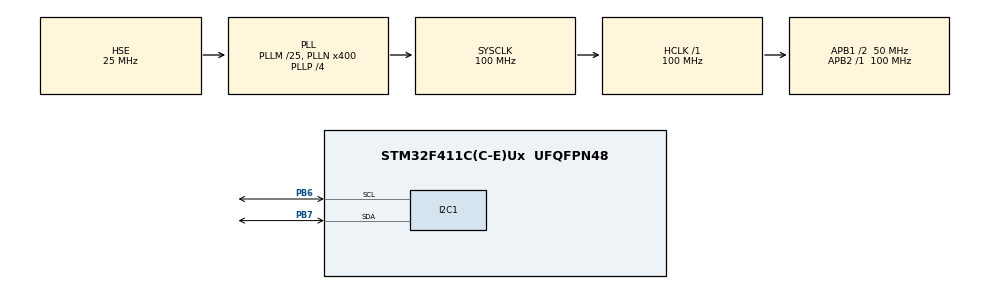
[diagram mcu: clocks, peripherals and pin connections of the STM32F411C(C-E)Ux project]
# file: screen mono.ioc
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I2C1.I2C_Mode=I2C_Fast
Mcu.Family=STM32F4
Mcu.Name=STM32F411C(C-E)Ux
Mcu.Package=UFQFPN48
NVIC.PriorityGroup=NVIC_PRIORITYGROUP_4
PB6.Mode=I2C
PB6.Signal=I2C1_SCL
PB7.Mode=I2C
PB7.Signal=I2C1_SDA
PH0\ -\ OSC_IN.Mode=HSE-External-Oscillator
PH0\ -\ OSC_IN.Signal=RCC_OSC_IN
PH1\ -\ OSC_OUT.Mode=HSE-External-Oscillator
PH1\ -\ OSC_OUT.Signal=RCC_OSC_OUT
ProjectManager.HeapSize=0x200
ProjectManager.StackSize=0x400
ProjectManager.TargetToolchain=STM32CubeIDE
RCC.48MHZClocksFreq_Value=100000000
RCC.AHBFreq_Value=100000000
RCC.APB1CLKDivider=RCC_HCLK_DIV2
RCC.APB1Freq_Value=50000000
RCC.APB1TimFreq_Value=100000000
RCC.APB2Freq_Value=100000000
RCC.APB2TimFreq_Value=100000000
RCC.CortexFreq_Value=100000000
RCC.HCLKFreq_Value=100000000
RCC.HSE_VALUE=25000000
RCC.HSI_VALUE=16000000
RCC.LSE_VALUE=32768
RCC.PLLM=25
RCC.PLLN=400
RCC.PLLP=RCC_PLLP_DIV4
RCC.PLLSourceVirtual=RCC_PLLSOURCE_HSE
RCC.SYSCLKFreq_VALUE=100000000
RCC.SYSCLKSource=RCC_SYSCLKSOURCE_PLLCLK
RCC.VCOOutputFreq_Value=400000000
board=custom

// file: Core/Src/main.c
/* USER CODE BEGIN Header */
/**
  ******************************************************************************
  * @file           : main.c
  * @brief          : Main program body
  ******************************************************************************
  * @attention
  *
  * Copyright (c) 2026 STMicroelectronics.
  * All rights reserved.
  *
  * This software is licensed under terms that can be found in the LICENSE file
  * in the root directory of this software component.
  * If no LICENSE file comes with this software, it is provided AS-IS.
  *
  ******************************************************************************
  */
/* USER CODE END Header */
#include "main.h"

/* USER CODE BEGIN PD */

#define SSD1315_I2C_ADDR  (0x3C << 1)

#define SCREEN_WIDTH 128
#define SCREEN_HEIGHT 64

/* USER CODE END PD */

I2C_HandleTypeDef hi2c1;

/* USER CODE BEGIN PV */

// Битовая матрица стандартного шрифта 8x16 (ASCII символы от ' ' до '~')
// Каждый байт — это одна строка символа шириной 8 пикселей. 1 - белый, 0 - черный.
const uint8_t font8x16[][16] = {
    // Здесь обычно находится весь массив ASCII. Ниже приведены только нужные нам символы для экономии места:
    ['H'] = {0x82, 0x82, 0x82, 0x82, 0x82, 0xFE, 0x82, 0x82, 0x82, 0x82, 0x82, 0x82, 0x82, 0x00, 0x00, 0x00},
    ['e'] = {0x00, 0x00, 0x00, 0x00, 0x00, 0x7C, 0x82, 0xFE, 0x80, 0x80, 0x82, 0x7C, 0x00, 0x00, 0x00, 0x00},
    ['l'] = {0x30, 0x10, 0x10, 0x10, 0x10, 0x10, 0x10, 0x10, 0x10, 0x10, 0x10, 0x18, 0x00, 0x00, 0x00, 0x00},
    ['o'] = {0x00, 0x00, 0x00, 0x00, 0x00, 0x7C, 0x82, 0x82, 0x82, 0x82, 0x82, 0x7C, 0x00, 0x00, 0x00, 0x00},
    [','] = {0x00, 0x00, 0x00, 0x00, 0x00, 0x00, 0x00, 0x00, 0x00, 0x00, 0x30, 0x30, 0x10, 0x20, 0x00, 0x00},
    [' '] = {0x00, 0x00, 0x00, 0x00, 0x00, 0x00, 0x00, 0x00, 0x00, 0x00, 0x00, 0x00, 0x00, 0x00, 0x00, 0x00},
    ['w'] = {0x00, 0x00, 0x00, 0x00, 0x00, 0x82, 0x82, 0x82, 0x92, 0x92, 0x92, 0x6C, 0x00, 0x00, 0x00, 0x00},
    ['r'] = {0x00, 0x00, 0x00, 0x00, 0x00, 0x9E, 0x62, 0x40, 0x40, 0x40, 0x40, 0xE0, 0x00, 0x00, 0x00, 0x00},
    ['d'] = {0x02, 0x02, 0x02, 0x7E, 0x82, 0x82, 0x82, 0x82, 0x82, 0x82, 0x86, 0x7A, 0x00, 0x00, 0x00, 0x00},
    ['!'] = {0x10, 0x10, 0x10, 0x10, 0x10, 0x10, 0x10, 0x10, 0x00, 0x00, 0x10, 0x10, 0x00, 0x00, 0x00, 0x00}
};

uint8_t screen_buffer[1024];

/* USER CODE END PV */

void SystemClock_Config(void);
static void MX_GPIO_Init(void);
static void MX_I2C1_Init(void);

/* USER CODE BEGIN 0 */

// Отправка одной управляющей команды
void SSD1315_WriteCommand(uint8_t cmd) {
    HAL_I2C_Mem_Write(&hi2c1, SSD1315_I2C_ADDR, 0x00, I2C_MEMADD_SIZE_8BIT, &cmd, 1, HAL_MAX_DELAY);
}

// Отправка всего буфера кадра на дисплей
void SSD1315_UpdateScreen(void) {
    // Возвращаем указатель адреса дисплея в начало (столбец 0, страница 0)
    SSD1315_WriteCommand(0x21); // Установка диапазона колонок
    SSD1315_WriteCommand(0);    // Старт
    SSD1315_WriteCommand(127);  // Конец

    SSD1315_WriteCommand(0x22); // Установка диапазона страниц (строк)
    SSD1315_WriteCommand(0);    // Старт
    SSD1315_WriteCommand(7);    // Конец (7 * 8 = 56, то есть до 63 строки)

    // Отправляем массив данных. Префикс 0x40 указывает, что это поток байт видеопамяти
    HAL_I2C_Mem_Write(&hi2c1, SSD1315_I2C_ADDR, 0x40, I2C_MEMADD_SIZE_8BIT, screen_buffer, 1024, HAL_MAX_DELAY);
}

void SSD1315_Init(void) {
    HAL_Delay(100); // Ждем стабилизации питания дисплея

    SSD1315_WriteCommand(0xAE); // Выключить дисплей (Sleep mode)

    SSD1315_WriteCommand(0x20); // Настройка адресации памяти
    SSD1315_WriteCommand(0x00); // 0x00 — Горизонтальная адресация (автоинкремент)

    SSD1315_WriteCommand(0xB0); // Установка стартового адреса страницы (0)

    SSD1315_WriteCommand(0xC8); // Переворот выходов COM (сканирование снизу вверх)
    SSD1315_WriteCommand(0x00); // Установка низшего адреса колонки
    SSD1315_WriteCommand(0x10); // Установка высшего адреса колонки
    SSD1315_WriteCommand(0x40); // Установка стартовой строки (0)

    SSD1315_WriteCommand(0x81); // Контрастность
    SSD1315_WriteCommand(0xCF); // Значение яркости от 0x00 до 0xFF

    SSD1315_WriteCommand(0xA1); // Переворот сегментов (разворот экрана по горизонтали)
    SSD1315_WriteCommand(0xA6); // Обычный режим (0xA7 — инверсный)

    SSD1315_WriteCommand(0xA8); // Мультиплексор (высота экрана)
    SSD1315_WriteCommand(0x3F); // 63 (для разрешения 128x64)

    SSD1315_WriteCommand(0xA4); // Вывод данных из RAM (0xA5 — включить все пиксели)
    SSD1315_WriteCommand(0xD3); // Смещение дисплея
    SSD1315_WriteCommand(0x00); // Без смещения

    SSD1315_WriteCommand(0xD5); // Частота генератора дисплея
    SSD1315_WriteCommand(0x80); // Рекомендуемое значение

    SSD1315_WriteCommand(0xD9); // Период предзаряда фаз
    SSD1315_WriteCommand(0xF1); // Рекомендуемое значение для SSD1315/SSD1306

    SSD1315_WriteCommand(0xDA); // Конфигурация пинов COM
    SSD1315_WriteCommand(0x12); // Альтернативная конфигурация (для 128x64)

    SSD1315_WriteCommand(0xDB); // Уровень VCOMH
    SSD1315_WriteCommand(0x40);

    SSD1315_WriteCommand(0x8D); // Управление встроенным насосом накачки (Charge Pump)
    SSD1315_WriteCommand(0x14); // 0x14 — Включить (без этого экран будет черным)

    SSD1315_WriteCommand(0xAF); // Включить дисплей (Display ON)
}

void SSD1315_DrawPixel(uint16_t x, uint16_t y, uint8_t color) {
    if (x >= 128 || y >= 64) {
    	return;
    }

    if (color) {
        screen_buffer[x + (y / 8) * 128] |= (1 << (y % 8));  // Зажечь пиксель
    } else {
        screen_buffer[x + (y / 8) * 128] &= ~(1 << (y % 8)); // Погасить пиксель
    }
}

void drawCross() {
	for (int i = 0; i < 1024; i++) {
		screen_buffer[i] = 0x00;
	}

	for (uint16_t i = 0; i < 64; i++) {
		SSD1315_DrawPixel(i * 2, i, 1);        // Линия из левого верхнего в правый нижний
		SSD1315_DrawPixel(127 - (i * 2), i, 1); // Линия из правого верхнего в левый нижний
	}

	SSD1315_UpdateScreen();
}

// Главная функция отрисовки сцены
void drawScene() {
    const char* text = "Hello, world!";
    int textLength = 13; // Количество символов в строке

    // Размеры одного символа в пикселях
    int charWidth = 8;
    int charHeight = 16;

    // Коэффициент масштабирования (увеличим текст в 2 раза, чтобы на 240х240 он не был слишком мелким)
    int scale = 1;

    // Вычисляем общую ширину и высоту текста на экране с учетом масштаба
    int totalTextWidth = textLength * charWidth * scale;
    int totalTextHeight = charHeight * scale;

    // Расчет начальных координат для идеального центра
    int startX = (SCREEN_WIDTH - totalTextWidth) / 2;   // (240 - 208) / 2 = 16
    int startY = (SCREEN_HEIGHT - totalTextHeight) / 2; // (240 - 32) / 2 = 104

	for (int i = 0; i < 1024; i++) {
		screen_buffer[i] = 0x00;
	}

    // 2. Посимвольный вывод надписи с масштабированием
    for (int i = 0; i < textLength; i++) {
        char ch = text[i];
        int charStartX = startX + (i * charWidth * scale);

        // Отрисовка символа построчно
        for (int row = 0; row < charHeight; row++) {
            uint8_t b = font8x16[(unsigned char)ch][row];
            for (int col = 0; col < charWidth; col++) {
                if (!(b & (0x80 >> col))) {
                	continue;
                }

                // Рисуем увеличенный пиксель (блок пикселей scale x scale)
                for (int sy = 0; sy < scale; sy++) {
                    for (int sx = 0; sx < scale; sx++) {
                    	SSD1315_DrawPixel(charStartX + (col * scale) + sx, startY + (row * scale) + sy, 1);
                    }
                }
            }
        }
    }

	SSD1315_UpdateScreen();
}

/* USER CODE END 0 */

int main(void)
{

  /* MCU Configuration--------------------------------------------------------*/

  /* Reset of all peripherals, Initializes the Flash interface and the Systick. */
  HAL_Init();

  /* Configure the system clock */
  SystemClock_Config();

  /* Initialize all configured peripherals */
  MX_GPIO_Init();
  MX_I2C1_Init();
  /* USER CODE BEGIN 2 */

  SSD1315_Init();

  drawCross();

  HAL_Delay(1500);

  drawScene();

  /* USER CODE END 2 */

  /* Infinite loop */
  while (1)
  {

  }
}

void SystemClock_Config(void)
{
  RCC_OscInitTypeDef RCC_OscInitStruct = {0};
  RCC_ClkInitTypeDef RCC_ClkInitStruct = {0};

  /** Configure the main internal regulator output voltage
  */
  __HAL_RCC_PWR_CLK_ENABLE();
  __HAL_PWR_VOLTAGESCALING_CONFIG(PWR_REGULATOR_VOLTAGE_SCALE1);

  /** Initializes the RCC Oscillators according to the specified parameters
  * in the RCC_OscInitTypeDef structure.
  */
  RCC_OscInitStruct.OscillatorType = RCC_OSCILLATORTYPE_HSE;
  RCC_OscInitStruct.HSEState = RCC_HSE_ON;
  RCC_OscInitStruct.PLL.PLLState = RCC_PLL_ON;
  RCC_OscInitStruct.PLL.PLLSource = RCC_PLLSOURCE_HSE;
  RCC_OscInitStruct.PLL.PLLM = 25;
  RCC_OscInitStruct.PLL.PLLN = 400;
  RCC_OscInitStruct.PLL.PLLP = RCC_PLLP_DIV4;
  RCC_OscInitStruct.PLL.PLLQ = 4;
  if (HAL_RCC_OscConfig(&RCC_OscInitStruct) != HAL_OK)
  {
    Error_Handler();
  }

  /** Initializes the CPU, AHB and APB buses clocks
  */
  RCC_ClkInitStruct.ClockType = RCC_CLOCKTYPE_HCLK|RCC_CLOCKTYPE_SYSCLK
                              |RCC_CLOCKTYPE_PCLK1|RCC_CLOCKTYPE_PCLK2;
  RCC_ClkInitStruct.SYSCLKSource = RCC_SYSCLKSOURCE_PLLCLK;
  RCC_ClkInitStruct.AHBCLKDivider = RCC_SYSCLK_DIV1;
  RCC_ClkInitStruct.APB1CLKDivider = RCC_HCLK_DIV2;
  RCC_ClkInitStruct.APB2CLKDivider = RCC_HCLK_DIV1;

  if (HAL_RCC_ClockConfig(&RCC_ClkInitStruct, FLASH_LATENCY_3) != HAL_OK)
  {
    Error_Handler();
  }
}

static void MX_I2C1_Init(void)
{

  hi2c1.Instance = I2C1;
  hi2c1.Init.ClockSpeed = 400000;
  hi2c1.Init.DutyCycle = I2C_DUTYCYCLE_2;
  hi2c1.Init.OwnAddress1 = 0;
  hi2c1.Init.AddressingMode = I2C_ADDRESSINGMODE_7BIT;
  hi2c1.Init.DualAddressMode = I2C_DUALADDRESS_DISABLE;
  hi2c1.Init.OwnAddress2 = 0;
  hi2c1.Init.GeneralCallMode = I2C_GENERALCALL_DISABLE;
  hi2c1.Init.NoStretchMode = I2C_NOSTRETCH_DISABLE;
  if (HAL_I2C_Init(&hi2c1) != HAL_OK)
  {
    Error_Handler();
  }

}

static void MX_GPIO_Init(void)
{

  /* GPIO Ports Clock Enable */
  __HAL_RCC_GPIOH_CLK_ENABLE();
  __HAL_RCC_GPIOB_CLK_ENABLE();

}

void Error_Handler(void)
{
  __disable_irq();
  while (1)
  {
  }
}
